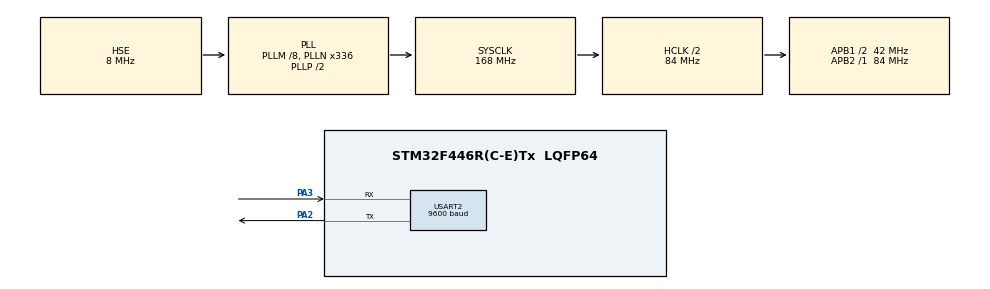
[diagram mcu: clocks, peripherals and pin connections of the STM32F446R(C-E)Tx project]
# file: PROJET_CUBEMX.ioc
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Mcu.Family=STM32F4
Mcu.Name=STM32F446R(C-E)Tx
Mcu.Package=LQFP64
NVIC.PriorityGroup=NVIC_PRIORITYGROUP_4
NVIC.RCC_IRQn=true\:0\:0\:false\:false\:true\:true\:false
PA2.Mode=Asynchronous
PA2.Signal=USART2_TX
PA3.Mode=Asynchronous
PA3.Signal=USART2_RX
PH0-OSC_IN.Mode=HSE-External-Oscillator
PH0-OSC_IN.Signal=RCC_OSC_IN
PH1-OSC_OUT.Mode=HSE-External-Oscillator
PH1-OSC_OUT.Signal=RCC_OSC_OUT
ProjectManager.HeapSize=0x200
ProjectManager.StackSize=0x400
ProjectManager.TargetToolchain=MDK-ARM V5.27
RCC.AHBCLKDivider=RCC_SYSCLK_DIV2
RCC.AHBFreq_Value=84000000
RCC.APB1CLKDivider=RCC_HCLK_DIV2
RCC.APB1Freq_Value=42000000
RCC.APB1TimFreq_Value=84000000
RCC.APB2Freq_Value=84000000
RCC.APB2TimFreq_Value=84000000
RCC.CortexFreq_Value=84000000
RCC.HCLKFreq_Value=84000000
RCC.HSE_VALUE=8000000
RCC.PLLM=8
RCC.PLLN=336
RCC.PLLSourceVirtual=RCC_PLLSOURCE_HSE
RCC.SYSCLKFreq_VALUE=168000000
RCC.SYSCLKSource=RCC_SYSCLKSOURCE_PLLCLK
RCC.USBFreq_Value=168000000
RCC.VCOOutputFreq_Value=336000000
USART2.BaudRate=9600
USART2.Parity=PARITY_EVEN
USART2.VirtualMode=VM_ASYNC
USART2.WordLength=WORDLENGTH_9B
board=custom

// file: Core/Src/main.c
/* USER CODE BEGIN Header */
/**
  ******************************************************************************
  * @file           : main.c
  * @brief          : Main program body
  ******************************************************************************
  * @attention
  *
  * <h2><center>&copy; Copyright (c) 2021 STMicroelectronics.
  * All rights reserved.</center></h2>
  *
  * This software component is licensed by ST under BSD 3-Clause license,
  * the "License"; You may not use this file except in compliance with the
  * License. You may obtain a copy of the License at:
  *                        opensource.org/licenses/BSD-3-Clause
  *
  ******************************************************************************
  */
/* USER CODE END Header */
#include "main.h"

/* USER CODE BEGIN Includes */
#include<stdio.h>
#include<string.h>
#include <ctype.h>
#include<stdlib.h>
#include<time.h>

/* USER CODE END Includes */

UART_HandleTypeDef huart2;

/* USER CODE BEGIN PV */
int toupper(int c);
int cesar26_chiffre(char* dst, int taille_dst, char* src);
int cesar26_dechiffre(char* dst, int taille_dst, char* src);
int cesarASCII_chiffre(char* dst, int taille_dst, char* src);
int cesarASCII_dechiffre(char* dst, int taille_dst, char* src);
int apply_xor8(char* dst, int taille_dst, char* src, unsigned char cle);
char annonce[50] = {0};
int nb;
int clef;
int clefXOR;
/* USER CODE END PV */

void SystemClock_Config(void);
static void MX_GPIO_Init(void);
static void MX_USART2_UART_Init(void);

int main(void)
{
  /* USER CODE BEGIN 1 */
	char mdp[81]= {'\0'};
	char mdp_encode[81]= {'\0'};
	char mdp_decode[81]= {'\0'};
	int i;

  /* USER CODE END 1 */

  /* MCU Configuration--------------------------------------------------------*/

  /* Reset of all peripherals, Initializes the Flash interface and the Systick. */
  HAL_Init();

  /* Configure the system clock */
  SystemClock_Config();

  /* Initialize all configured peripherals */
  MX_GPIO_Init();
  MX_USART2_UART_Init();
  /* USER CODE BEGIN 2 */
	nb = sprintf(annonce, "Veuillez entrer votre mot de passe\n\r");
	HAL_UART_Transmit(&huart2, (uint8_t*)annonce, nb, 1000);

	while (mdp[0]=='\0'){
					HAL_UART_Receive(&huart2, (uint8_t*)mdp, sizeof(mdp), 5000);
			}

	for (i=0; mdp[i]!='\0'; i++);//trouver la taille
	srand(mdp[0]+i*rand());//srand depend du premier caractere de la chaine + de la taille
	clef = rand()%26;
	srand(mdp[0]+i*rand());//srand depend du premier caractere de la chaine + de la taille
	clefXOR = rand()%255;
	nb = sprintf(annonce, "%s\n\r", mdp);
	HAL_UART_Transmit(&huart2, (uint8_t*)annonce, nb, 1000);
	//cesar26_chiffre(mdp_encode, 81, mdp);
	//cesar26_dechiffre(mdp_decode, 81, mdp_encode);
	//cesarASCII_chiffre (mdp_encode, 81, mdp);
  //cesarASCII_dechiffre (mdp_decode, 81, mdp_encode);
	apply_xor8(mdp_encode, 81, mdp, clefXOR);

  /* USER CODE END 2 */

  /* Infinite loop */
  while (1)
  {

  }
}

void SystemClock_Config(void)
{
  RCC_OscInitTypeDef RCC_OscInitStruct = {0};
  RCC_ClkInitTypeDef RCC_ClkInitStruct = {0};

  /** Configure the main internal regulator output voltage
  */
  __HAL_RCC_PWR_CLK_ENABLE();
  __HAL_PWR_VOLTAGESCALING_CONFIG(PWR_REGULATOR_VOLTAGE_SCALE3);
  /** Initializes the RCC Oscillators according to the specified parameters
  * in the RCC_OscInitTypeDef structure.
  */
  RCC_OscInitStruct.OscillatorType = RCC_OSCILLATORTYPE_HSE;
  RCC_OscInitStruct.HSEState = RCC_HSE_ON;
  RCC_OscInitStruct.PLL.PLLState = RCC_PLL_ON;
  RCC_OscInitStruct.PLL.PLLSource = RCC_PLLSOURCE_HSE;
  RCC_OscInitStruct.PLL.PLLM = 8;
  RCC_OscInitStruct.PLL.PLLN = 336;
  RCC_OscInitStruct.PLL.PLLP = RCC_PLLP_DIV2;
  RCC_OscInitStruct.PLL.PLLQ = 2;
  RCC_OscInitStruct.PLL.PLLR = 2;
  if (HAL_RCC_OscConfig(&RCC_OscInitStruct) != HAL_OK)
  {
    Error_Handler();
  }
  /** Initializes the CPU, AHB and APB buses clocks
  */
  RCC_ClkInitStruct.ClockType = RCC_CLOCKTYPE_HCLK|RCC_CLOCKTYPE_SYSCLK
                              |RCC_CLOCKTYPE_PCLK1|RCC_CLOCKTYPE_PCLK2;
  RCC_ClkInitStruct.SYSCLKSource = RCC_SYSCLKSOURCE_PLLCLK;
  RCC_ClkInitStruct.AHBCLKDivider = RCC_SYSCLK_DIV2;
  RCC_ClkInitStruct.APB1CLKDivider = RCC_HCLK_DIV2;
  RCC_ClkInitStruct.APB2CLKDivider = RCC_HCLK_DIV1;

  if (HAL_RCC_ClockConfig(&RCC_ClkInitStruct, FLASH_LATENCY_2) != HAL_OK)
  {
    Error_Handler();
  }
}

static void MX_USART2_UART_Init(void)
{

  huart2.Instance = USART2;
  huart2.Init.BaudRate = 9600;
  huart2.Init.WordLength = UART_WORDLENGTH_9B;
  huart2.Init.StopBits = UART_STOPBITS_1;
  huart2.Init.Parity = UART_PARITY_EVEN;
  huart2.Init.Mode = UART_MODE_TX_RX;
  huart2.Init.HwFlowCtl = UART_HWCONTROL_NONE;
  huart2.Init.OverSampling = UART_OVERSAMPLING_16;
  if (HAL_UART_Init(&huart2) != HAL_OK)
  {
    Error_Handler();
  }

}

static void MX_GPIO_Init(void)
{

  /* GPIO Ports Clock Enable */
  __HAL_RCC_GPIOH_CLK_ENABLE();
  __HAL_RCC_GPIOA_CLK_ENABLE();

}

/* USER CODE BEGIN 4 */
int cesar26_chiffre(char* dst, int taille_dst, char* src)
{
    int i;
    int j=0;
    int rang;

    for (i = 0; src[i] != '\0'; i++)
    {
       src[i] = toupper(src[i]); //maintenant, chaine tout en maj, on peut commencer l'encodage
    }

		//nb = sprintf(annonce, "Veuillez entrer la cle d'encodage\n\r");
		//HAL_UART_Transmit(&huart2, (uint8_t*)annonce, nb, 1000);

		nb = sprintf(annonce, "clef = %d\n\r", clef);
		HAL_UART_Transmit(&huart2, (uint8_t*)annonce, nb, 1000);

    while(src[j] != '\0')
    {
        if (src[j] >= 'A' && src[j] <= 'Z' ){
            rang = src[j] - 'A';
            rang = (rang + clef) % 26;
            if(rang < 0) rang += 26;
            dst[j] = 'A' + rang;
        }
        else {
            dst[j] = src[j];
        }
        j++;
    }
    dst[j] = '\0';

		nb = sprintf(annonce, "MDP encode : %s\n\r", dst);
		HAL_UART_Transmit(&huart2, (uint8_t*)annonce, nb, 1000);

    return 0;
}

int cesar26_dechiffre(char* dst, int taille_dst, char* src)
{
    int i;
    int j=0;
    int rang;

		nb = sprintf(annonce, "clef = %d\n\r", clef);
		HAL_UART_Transmit(&huart2, (uint8_t*)annonce, nb, 1000);

    while(src[j] != '\0')
    {
        if (src[j] >= 'A' && src[j] <= 'Z' ){
            rang = src[j] - 'A';
            rang = (rang - clef) % 26;
            if(rang < 0) rang += 26;
            dst[j] = 'A' + rang;
        }
        else {
            dst[j] = src[j];
        }
        j++;
    }
    dst[j] = '\0';

    nb = sprintf(annonce, "MDP decode : %s\n\r", dst);
		HAL_UART_Transmit(&huart2, (uint8_t*)annonce, nb, 1000);

    return 0;
}

int cesarASCII_chiffre(char* dst, int taille_dst, char* src)
{
    int i;
    int j=0;
    int rang;

		nb = sprintf(annonce, "clef = %d\n\r", clef);
		HAL_UART_Transmit(&huart2, (uint8_t*)annonce, nb, 1000);

    while(src[j] != '\0')
    {
            rang = src[j] - 32;
            rang = (rang + clef) % 95;
            if(rang < 0) rang += 95;
            dst[j] = 32 + rang;

        j++;
    }
    dst[j] = '\0';

		nb = sprintf(annonce, "MDP encode : %s\n\r", dst);
		HAL_UART_Transmit(&huart2, (uint8_t*)annonce, nb, 1000);

    return 0;
}

int cesarASCII_dechiffre(char* dst, int taille_dst, char* src)
{
    int i;
    int j=0;
    int rang;

		nb = sprintf(annonce, "clef = %d\n\r", clef);
		HAL_UART_Transmit(&huart2, (uint8_t*)annonce, nb, 1000);

    while(src[j] != '\0')
    {
            rang = src[j] - 32;
            rang = (rang - clef) % 95;
            if(rang < 0) rang += 95;
            dst[j] = 32 + rang;

        j++;
    }
    dst[j] = '\0';

    nb = sprintf(annonce, "MDP decode : %s\n\r", dst);
		HAL_UART_Transmit(&huart2, (uint8_t*)annonce, nb, 1000);

    return 0;
}
int apply_xor8(char* dst, int taille_dst, char* src, unsigned char cle)
{
    int j,i;
    unsigned char y;
    unsigned char decode[50];
		nb = sprintf(annonce, "\n\r cle = %d ", cle);
		HAL_UART_Transmit(&huart2, (uint8_t*)annonce, nb, 1000);
    nb = sprintf(annonce, "MDP encode : ");
		HAL_UART_Transmit(&huart2, (uint8_t*)annonce, nb, 1000);

    for (j=0; src[j]!='\0'; j++)
    {
				nb = sprintf(annonce, "\n\rsrc = %c ", src[j]);
				HAL_UART_Transmit(&huart2, (uint8_t*)annonce, nb, 1000);
        y = src[j]^cle;
				dst[j] = y;
				nb = sprintf(annonce, "\n\r%x ", dst[j]);
				HAL_UART_Transmit(&huart2, (uint8_t*)annonce, nb, 1000);
    }
    nb = sprintf(annonce, "MDP decode : ");
		HAL_UART_Transmit(&huart2, (uint8_t*)annonce, nb, 1000);
    for (i=0; dst[i]!='\0'; i++)
    {
        decode [i] = dst[i]^cle;
				nb = sprintf(annonce, "%c ", decode[i]);
				HAL_UART_Transmit(&huart2, (uint8_t*)annonce, nb, 1000);
    }
}
/* USER CODE END 4 */

void Error_Handler(void)
{
  __disable_irq();
  while (1)
  {
  }
}

/************************ (C) COPYRIGHT STMicroelectronics *****END OF FILE****/
